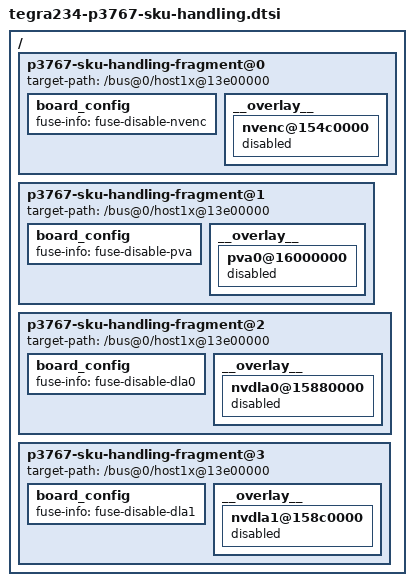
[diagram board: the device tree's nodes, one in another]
// SPDX-FileCopyrightText: Copyright (c) 2023 NVIDIA CORPORATION & AFFILIATES. All rights reserved.
// SPDX-License-Identifier: GPL-2.0-only

/ {
	p3767-sku-handling-fragment@0 {
		target-path = "/bus@0/host1x@13e00000";
		board_config {
			fuse-info = "fuse-disable-nvenc";
		};
		__overlay__ {
			nvenc@154c0000 {
				status = "disabled";
			};
		};
	};

	p3767-sku-handling-fragment@1 {
		target-path = "/bus@0/host1x@13e00000";
		board_config {
			fuse-info = "fuse-disable-pva";
		};
		__overlay__ {
			pva0@16000000 {
				status = "disabled";
			};
		};
	};

	p3767-sku-handling-fragment@2 {
		target-path = "/bus@0/host1x@13e00000";
		board_config {
			fuse-info = "fuse-disable-dla0";
		};
		__overlay__ {
			nvdla0@15880000 {
				status = "disabled";
			};
		};
	};

	p3767-sku-handling-fragment@3 {
		target-path = "/bus@0/host1x@13e00000";
		board_config {
			fuse-info = "fuse-disable-dla1";
		};
		__overlay__ {
			nvdla1@158c0000 {
				status = "disabled";
			};
		};
	};
};
